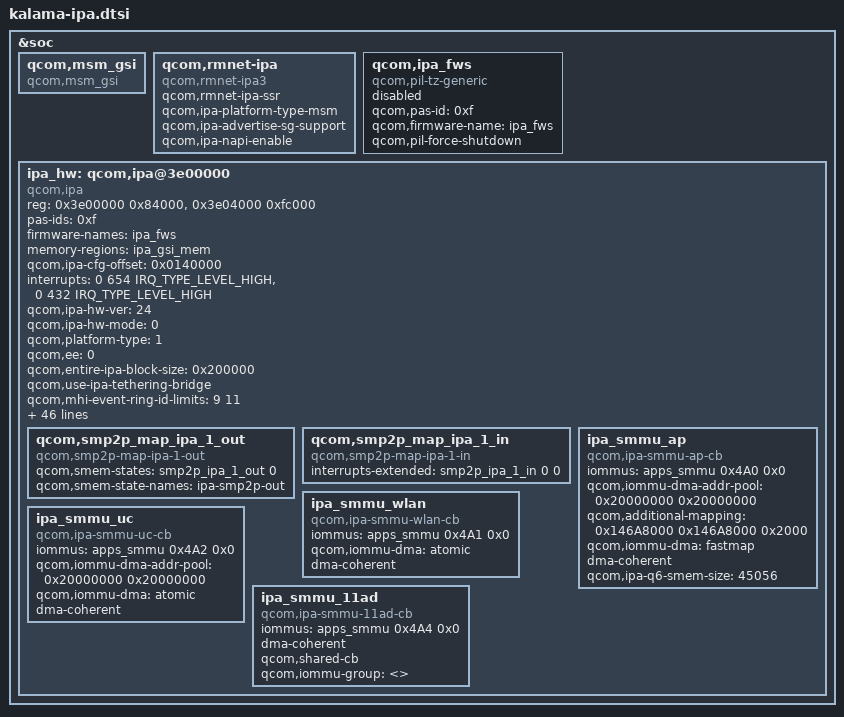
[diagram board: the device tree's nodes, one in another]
&soc {
        qcom,msm_gsi {
                compatible = "qcom,msm_gsi";
        };

        qcom,rmnet-ipa {
                compatible = "qcom,rmnet-ipa3";
                qcom,rmnet-ipa-ssr;
                qcom,ipa-platform-type-msm;
                qcom,ipa-advertise-sg-support;
                qcom,ipa-napi-enable;
        };

        qcom,ipa_fws {
                compatible = "qcom,pil-tz-generic";
                qcom,pas-id = <0xf>;
                qcom,firmware-name = "ipa_fws";
                qcom,pil-force-shutdown;
                status = "disabled";
        };

        ipa_hw: qcom,ipa@3e00000 {
                compatible = "qcom,ipa";
                reg =
                        <0x3e00000 0x84000>,
                        <0x3e04000 0xfc000>;
                reg-names = "ipa-base", "gsi-base";
                pas-ids = <0xf>;
                firmware-names = "ipa_fws";
                memory-regions = <&ipa_gsi_mem>;
                qcom,ipa-cfg-offset = <0x0140000>;
                interrupts =
                        <0 654 IRQ_TYPE_LEVEL_HIGH>,
                        <0 432 IRQ_TYPE_LEVEL_HIGH>;
                interrupt-names = "ipa-irq", "gsi-irq";
                qcom,ipa-hw-ver = <24>; /* IPA core version = IPAv5.5 */
                qcom,ipa-hw-mode = <0>;
                qcom,platform-type = <1>; /* MSM platform */
                qcom,ee = <0>;
		qcom,entire-ipa-block-size = <0x200000>;
                qcom,use-ipa-tethering-bridge;
                qcom,mhi-event-ring-id-limits = <9 11>; /* start and end */
                qcom,modem-cfg-emb-pipe-flt;
                qcom,ipa-wdi3-over-gsi;
                qcom,arm-smmu;
                qcom,smmu-fast-map;
                qcom,use-64-bit-dma-mask;
                qcom,ipa-endp-delay-wa-v2;
                qcom,lan-rx-napi;
                qcom,tx-napi;
                qcom,tx-poll;
		qcom,register-collection-on-crash;
		qcom,testbus-collection-on-crash;
		qcom,non-tn-collection-on-crash;
                qcom,wan-use-skb-page;
                qcom,rmnet-ctl-enable;
                qcom,rmnet-ll-enable;
                qcom,ipa-uc-holb-monitor;
                qcom,ipa-holb-monitor-poll-period = <5>;
                qcom,ipa-holb-monitor-max-cnt-wlan = <10>;
                qcom,ipa-holb-monitor-max-cnt-usb = <10>;
                qcom,ipa-holb-monitor-max-cnt-11ad = <10>;
                qcom,tx-wrapper-cache-max-size = <400>;
                qcom,ipa-gpi-event-rp-ddr;
                qcom,ulso-supported;
                qcom,ulso-ip-id-min-linux-val = <0>;
                qcom,ulso-ip-id-max-linux-val = <0xffff>;
                qcom,ulso-ip-id-min-windows-val = <0>;
                qcom,ulso-ip-id-max-windows-val = <0x7fff>;
                qcom,max_num_smmu_cb = <4>;
                clock-names = "core_clk";
                clocks = <&rpmhcc RPMH_IPA_CLK>;
                qcom,interconnect,num-cases = <5>;
                qcom,interconnect,num-paths = <3>;
                interconnects = <&aggre2_noc MASTER_IPA &gem_noc SLAVE_LLCC>,
                        <&mc_virt MASTER_LLCC &mc_virt SLAVE_EBI1>,
                        <&gem_noc MASTER_APPSS_PROC &config_noc SLAVE_IPA_CFG>;
                interconnect-names = "ipa_to_llcc", "llcc_to_ebi1", "appss_to_ipa";
                /* No vote */
                qcom,no-vote =
                <0 0 0 0 0 0>;

                /* SVS2 */
                qcom,svs2 =
                <0 0 0 1300000 0 76800>;

                /* SVS */
                qcom,svs =
                <1200000 0 1200000 2800000 0 150000>;

                /* NOMINAL */
                qcom,nominal =
                <2400000 0 2400000 5500000 0 400000>;

                /* TURBO */
                qcom,turbo =
                <3600000 0 3600000 5500000 0 400000>;

                qcom,bus-vector-names = "MIN", "SVS2", "SVS", "NOMINAL",
                        "TURBO";
                qcom,throughput-threshold = <2000 4000 8000>;
                qcom,scaling-exceptions = <>;

                /* smp2p information */
                qcom,smp2p_map_ipa_1_out {
                        compatible = "qcom,smp2p-map-ipa-1-out";
                        qcom,smem-states = <&smp2p_ipa_1_out 0>;
                        qcom,smem-state-names = "ipa-smp2p-out";
                };

                qcom,smp2p_map_ipa_1_in {
                        compatible = "qcom,smp2p-map-ipa-1-in";
                        interrupts-extended = <&smp2p_ipa_1_in 0 0>;
                        interrupt-names = "ipa-smp2p-in";
                };

                ipa_smmu_ap: ipa_smmu_ap {
                        compatible = "qcom,ipa-smmu-ap-cb";
                        iommus = <&apps_smmu 0x4A0 0x0>;
                        qcom,iommu-dma-addr-pool = <0x20000000 0x20000000>;
                        qcom,additional-mapping =
                                /* modem tables in IMEM */
                                <0x146A8000 0x146A8000 0x2000>;
                        qcom,iommu-dma = "fastmap";
                        dma-coherent;
                        qcom,ipa-q6-smem-size = <45056>;
                };

                ipa_smmu_wlan: ipa_smmu_wlan {
                        compatible = "qcom,ipa-smmu-wlan-cb";
                        iommus = <&apps_smmu 0x4A1 0x0>;
                        qcom,iommu-dma = "atomic";
                        dma-coherent;
                };

                ipa_smmu_uc: ipa_smmu_uc {
                        compatible = "qcom,ipa-smmu-uc-cb";
                        iommus = <&apps_smmu 0x4A2 0x0>;
                        qcom,iommu-dma-addr-pool = <0x20000000 0x20000000>;
                        qcom,iommu-dma = "atomic";
                        dma-coherent;
                };

                ipa_smmu_11ad: ipa_smmu_11ad {
                        compatible = "qcom,ipa-smmu-11ad-cb";
                        iommus = <&apps_smmu 0x4A4 0x0>;
                        dma-coherent;
                        qcom,shared-cb;
                        qcom,iommu-group = <>;
                };
        };
};
